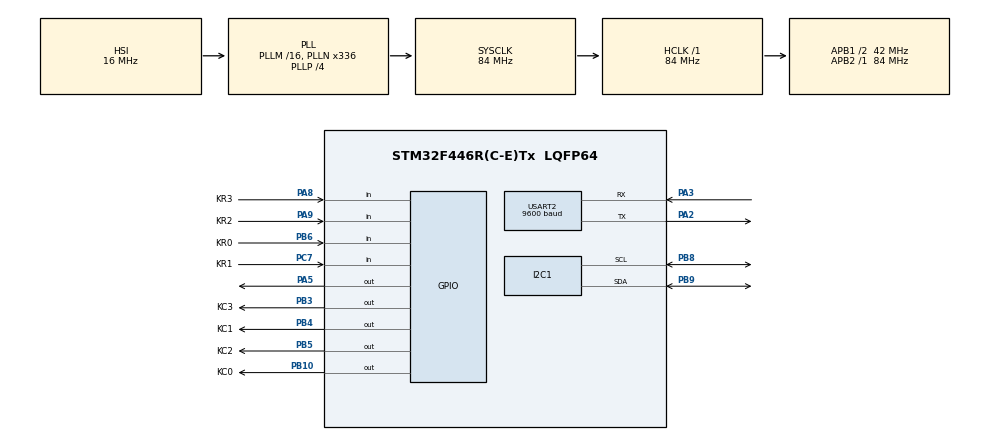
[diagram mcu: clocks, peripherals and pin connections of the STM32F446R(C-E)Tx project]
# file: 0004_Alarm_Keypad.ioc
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I2C1.I2C_Mode=I2C_Fast
Mcu.Family=STM32F4
Mcu.Name=STM32F446R(C-E)Tx
Mcu.Package=LQFP64
NVIC.PriorityGroup=NVIC_PRIORITYGROUP_0
NVIC.TIM6_DAC_IRQn=true\:0\:0\:false\:false\:true\:false\:true\:true
NVIC.TimeBase=TIM6_DAC_IRQn
NVIC.TimeBaseIP=TIM6
PA13.Mode=Serial_Wire
PA13.Signal=SYS_JTMS-SWDIO
PA14.Mode=Serial_Wire
PA14.Signal=SYS_JTCK-SWCLK
PA2.Mode=Asynchronous
PA2.Signal=USART2_TX
PA3.Mode=Asynchronous
PA3.Signal=USART2_RX
PA5.Signal=GPIO_Output
PA8.GPIO_Label=KR3
PA8.GPIO_PuPd=GPIO_PULLDOWN
PA8.Signal=GPIO_Input
PA9.GPIO_Label=KR2
PA9.GPIO_PuPd=GPIO_PULLDOWN
PA9.Signal=GPIO_Input
PB10.GPIO_Label=KC0
PB10.Signal=GPIO_Output
PB3.GPIO_Label=KC3
PB3.Signal=GPIO_Output
PB4.GPIO_Label=KC1
PB4.Signal=GPIO_Output
PB5.GPIO_Label=KC2
PB5.Signal=GPIO_Output
PB6.GPIO_Label=KR0
PB6.GPIO_PuPd=GPIO_PULLDOWN
PB6.Signal=GPIO_Input
PB8.Mode=I2C
PB8.Signal=I2C1_SCL
PB9.Mode=I2C
PB9.Signal=I2C1_SDA
PC14-OSC32_IN.Mode=LSE-External-Oscillator
PC14-OSC32_IN.Signal=RCC_OSC32_IN
PC15-OSC32_OUT.Mode=LSE-External-Oscillator
PC15-OSC32_OUT.Signal=RCC_OSC32_OUT
PC7.GPIO_Label=KR1
PC7.GPIO_PuPd=GPIO_PULLDOWN
PC7.Signal=GPIO_Input
PH0-OSC_IN.Mode=HSE-External-Oscillator
PH0-OSC_IN.Signal=RCC_OSC_IN
PH1-OSC_OUT.Mode=HSE-External-Oscillator
PH1-OSC_OUT.Signal=RCC_OSC_OUT
ProjectManager.HeapSize=0x200
ProjectManager.StackSize=0x400
ProjectManager.TargetToolchain=STM32CubeIDE
RCC.48MHZClocksFreq_Value=84000000
RCC.AHBFreq_Value=84000000
RCC.APB1CLKDivider=RCC_HCLK_DIV2
RCC.APB1Freq_Value=42000000
RCC.APB1TimFreq_Value=84000000
RCC.APB2Freq_Value=84000000
RCC.APB2TimFreq_Value=84000000
RCC.CortexFreq_Value=84000000
RCC.FLatency-AdvancedSettings=FLASH_LATENCY_2
RCC.HCLKFreq_Value=84000000
RCC.HSE_VALUE=8000000
RCC.HSI_VALUE=16000000
RCC.PLLN=336
RCC.PLLP=RCC_PLLP_DIV4
RCC.SYSCLKFreq_VALUE=84000000
RCC.SYSCLKSource=RCC_SYSCLKSOURCE_PLLCLK
RCC.USBFreq_Value=168000000
RCC.VCOOutputFreq_Value=336000000
USART2.BaudRate=9600
USART2.VirtualMode=VM_ASYNC
VP_SYS_VS_tim6.Mode=TIM6
board=NUCLEO-F446RE

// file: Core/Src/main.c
/* USER CODE BEGIN Header */
/**
  ******************************************************************************
  * @file           : main.c
  * @brief          : Main program body
  ******************************************************************************
  * @attention
  *
  * Copyright (c) 2024 STMicroelectronics.
  * All rights reserved.
  *
  * This software is licensed under terms that can be found in the LICENSE file
  * in the root directory of this software component.
  * If no LICENSE file comes with this software, it is provided AS-IS.
  *
  ******************************************************************************
  */
/* USER CODE END Header */
#include "main.h"

/* USER CODE BEGIN Includes */
#include "Keypad4X4.h"
#include <stdio.h>
#include <string.h>
#include <stdlib.h>
#include "fonts.h"
#include "ssd1306.h"

/* USER CODE END Includes */

I2C_HandleTypeDef hi2c1;

UART_HandleTypeDef huart2;

/* USER CODE BEGIN PV */
extern char key;
char hold[4];
char entered_code[5] = "";
const char correct_code[] = "1234";
int code_index = 0;
/* USER CODE END PV */

void SystemClock_Config(void);
static void MX_GPIO_Init(void);
static void MX_USART2_UART_Init(void);
static void MX_I2C1_Init(void);

/* USER CODE END Includes */

int main(void)
{
    HAL_Init();
    SystemClock_Config();
    MX_GPIO_Init();
    MX_USART2_UART_Init();
    MX_I2C1_Init();

    SSD1306_Init();
    SSD1306_GotoXY(0, 0);
    SSD1306_Puts("Enter Code:", &Font_11x18, 1);
    SSD1306_UpdateScreen();
    HAL_Delay(500);

    while (1)
    {
        key = Get_Key();
        if (key != 0) // If a key is pressed
        {
            entered_code[code_index++] = key;
            SSD1306_GotoXY(0, 30);
            SSD1306_Puts("*",&Font_11x18, 1);
            SSD1306_UpdateScreen();

            if (code_index == 4) // After entering 4 digits
            {
                entered_code[4] = '\0'; // Null terminate the string
                SSD1306_GotoXY(0, 50);

                if (strcmp(entered_code, correct_code) == 0)
                {
                    SSD1306_Puts("Correct", &Font_11x18, 1);
                    HAL_GPIO_WritePin(GPIOA, GPIO_PIN_5, GPIO_PIN_SET); // Turn on LED
                }
                else
                {
                    SSD1306_Puts("Incorrect", &Font_11x18, 1);
                    HAL_GPIO_WritePin(GPIOA, GPIO_PIN_5, GPIO_PIN_RESET); // Turn off LED
                }

                SSD1306_UpdateScreen();
                HAL_Delay(2000);

                // Reset input for new entry
                memset(entered_code, 0, sizeof(entered_code));
                code_index = 0;
                SSD1306_Clear();
                SSD1306_GotoXY(0, 0);
                SSD1306_Puts("Enter Code:", &Font_11x18, 1);
                SSD1306_UpdateScreen();
            }
        }
    }
}

void SystemClock_Config(void)
{
  RCC_OscInitTypeDef RCC_OscInitStruct = {0};
  RCC_ClkInitTypeDef RCC_ClkInitStruct = {0};

  /** Configure the main internal regulator output voltage
  */
  __HAL_RCC_PWR_CLK_ENABLE();
  __HAL_PWR_VOLTAGESCALING_CONFIG(PWR_REGULATOR_VOLTAGE_SCALE3);

  /** Initializes the RCC Oscillators according to the specified parameters
  * in the RCC_OscInitTypeDef structure.
  */
  RCC_OscInitStruct.OscillatorType = RCC_OSCILLATORTYPE_HSI;
  RCC_OscInitStruct.HSIState = RCC_HSI_ON;
  RCC_OscInitStruct.HSICalibrationValue = RCC_HSICALIBRATION_DEFAULT;
  RCC_OscInitStruct.PLL.PLLState = RCC_PLL_ON;
  RCC_OscInitStruct.PLL.PLLSource = RCC_PLLSOURCE_HSI;
  RCC_OscInitStruct.PLL.PLLM = 16;
  RCC_OscInitStruct.PLL.PLLN = 336;
  RCC_OscInitStruct.PLL.PLLP = RCC_PLLP_DIV4;
  RCC_OscInitStruct.PLL.PLLQ = 2;
  RCC_OscInitStruct.PLL.PLLR = 2;
  if (HAL_RCC_OscConfig(&RCC_OscInitStruct) != HAL_OK)
  {
    Error_Handler();
  }

  /** Initializes the CPU, AHB and APB buses clocks
  */
  RCC_ClkInitStruct.ClockType = RCC_CLOCKTYPE_HCLK|RCC_CLOCKTYPE_SYSCLK
                              |RCC_CLOCKTYPE_PCLK1|RCC_CLOCKTYPE_PCLK2;
  RCC_ClkInitStruct.SYSCLKSource = RCC_SYSCLKSOURCE_PLLCLK;
  RCC_ClkInitStruct.AHBCLKDivider = RCC_SYSCLK_DIV1;
  RCC_ClkInitStruct.APB1CLKDivider = RCC_HCLK_DIV2;
  RCC_ClkInitStruct.APB2CLKDivider = RCC_HCLK_DIV1;

  if (HAL_RCC_ClockConfig(&RCC_ClkInitStruct, FLASH_LATENCY_2) != HAL_OK)
  {
    Error_Handler();
  }
}

static void MX_I2C1_Init(void)
{

  hi2c1.Instance = I2C1;
  hi2c1.Init.ClockSpeed = 400000;
  hi2c1.Init.DutyCycle = I2C_DUTYCYCLE_2;
  hi2c1.Init.OwnAddress1 = 0;
  hi2c1.Init.AddressingMode = I2C_ADDRESSINGMODE_7BIT;
  hi2c1.Init.DualAddressMode = I2C_DUALADDRESS_DISABLE;
  hi2c1.Init.OwnAddress2 = 0;
  hi2c1.Init.GeneralCallMode = I2C_GENERALCALL_DISABLE;
  hi2c1.Init.NoStretchMode = I2C_NOSTRETCH_DISABLE;
  if (HAL_I2C_Init(&hi2c1) != HAL_OK)
  {
    Error_Handler();
  }

}

static void MX_USART2_UART_Init(void)
{

  huart2.Instance = USART2;
  huart2.Init.BaudRate = 9600;
  huart2.Init.WordLength = UART_WORDLENGTH_8B;
  huart2.Init.StopBits = UART_STOPBITS_1;
  huart2.Init.Parity = UART_PARITY_NONE;
  huart2.Init.Mode = UART_MODE_TX_RX;
  huart2.Init.HwFlowCtl = UART_HWCONTROL_NONE;
  huart2.Init.OverSampling = UART_OVERSAMPLING_16;
  if (HAL_UART_Init(&huart2) != HAL_OK)
  {
    Error_Handler();
  }

}

static void MX_GPIO_Init(void)
{
  GPIO_InitTypeDef GPIO_InitStruct = {0};

  /* GPIO Ports Clock Enable */
  __HAL_RCC_GPIOC_CLK_ENABLE();
  __HAL_RCC_GPIOH_CLK_ENABLE();
  __HAL_RCC_GPIOA_CLK_ENABLE();
  __HAL_RCC_GPIOB_CLK_ENABLE();

  /*Configure GPIO pin Output Level */
  HAL_GPIO_WritePin(GPIOA, GPIO_PIN_5, GPIO_PIN_RESET);

  /*Configure GPIO pin Output Level */
  HAL_GPIO_WritePin(GPIOB, KC0_Pin|KC3_Pin|KC1_Pin|KC2_Pin, GPIO_PIN_RESET);

  /*Configure GPIO pin : PA5 */
  GPIO_InitStruct.Pin = GPIO_PIN_5;
  GPIO_InitStruct.Mode = GPIO_MODE_OUTPUT_PP;
  GPIO_InitStruct.Pull = GPIO_NOPULL;
  GPIO_InitStruct.Speed = GPIO_SPEED_FREQ_LOW;
  HAL_GPIO_Init(GPIOA, &GPIO_InitStruct);

  /*Configure GPIO pins : KC0_Pin KC3_Pin KC1_Pin KC2_Pin */
  GPIO_InitStruct.Pin = KC0_Pin|KC3_Pin|KC1_Pin|KC2_Pin;
  GPIO_InitStruct.Mode = GPIO_MODE_OUTPUT_PP;
  GPIO_InitStruct.Pull = GPIO_NOPULL;
  GPIO_InitStruct.Speed = GPIO_SPEED_FREQ_LOW;
  HAL_GPIO_Init(GPIOB, &GPIO_InitStruct);

  /*Configure GPIO pin : KR1_Pin */
  GPIO_InitStruct.Pin = KR1_Pin;
  GPIO_InitStruct.Mode = GPIO_MODE_INPUT;
  GPIO_InitStruct.Pull = GPIO_PULLDOWN;
  HAL_GPIO_Init(KR1_GPIO_Port, &GPIO_InitStruct);

  /*Configure GPIO pins : KR3_Pin KR2_Pin */
  GPIO_InitStruct.Pin = KR3_Pin|KR2_Pin;
  GPIO_InitStruct.Mode = GPIO_MODE_INPUT;
  GPIO_InitStruct.Pull = GPIO_PULLDOWN;
  HAL_GPIO_Init(GPIOA, &GPIO_InitStruct);

  /*Configure GPIO pin : KR0_Pin */
  GPIO_InitStruct.Pin = KR0_Pin;
  GPIO_InitStruct.Mode = GPIO_MODE_INPUT;
  GPIO_InitStruct.Pull = GPIO_PULLDOWN;
  HAL_GPIO_Init(KR0_GPIO_Port, &GPIO_InitStruct);

}

void HAL_TIM_PeriodElapsedCallback(TIM_HandleTypeDef *htim)
{
  if (htim->Instance == TIM6) {
    HAL_IncTick();
  }
}

void Error_Handler(void)
{
  __disable_irq();
  while (1)
  {
  }
}
